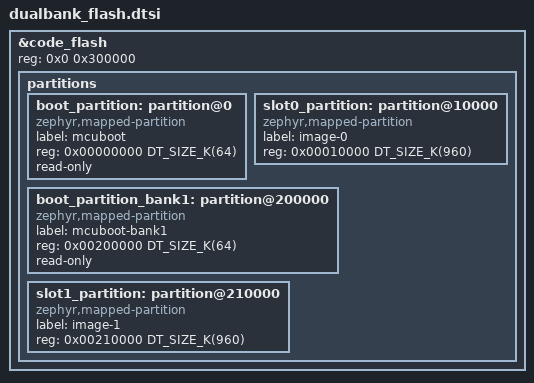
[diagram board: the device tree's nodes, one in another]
&code_flash {
	reg = <0x0 0x300000>;
	ranges = <0x0 0x0 0x300000>;

	partitions {
		#address-cells = <1>;
		#size-cells = <1>;
		ranges;

		boot_partition: partition@0 {
			compatible = "zephyr,mapped-partition";
			label = "mcuboot";
			reg = <0x00000000 DT_SIZE_K(64)>;
			read-only;
		};

		slot0_partition: partition@10000 {
			compatible = "zephyr,mapped-partition";
			label = "image-0";
			reg = <0x00010000 DT_SIZE_K(960)>;
		};

		boot_partition_bank1: partition@200000 {
			compatible = "zephyr,mapped-partition";
			label = "mcuboot-bank1";
			reg = <0x00200000 DT_SIZE_K(64)>;
			read-only;
		};

		slot1_partition: partition@210000 {
			compatible = "zephyr,mapped-partition";
			label = "image-1";
			reg = <0x00210000 DT_SIZE_K(960)>;
		};
	};
};
